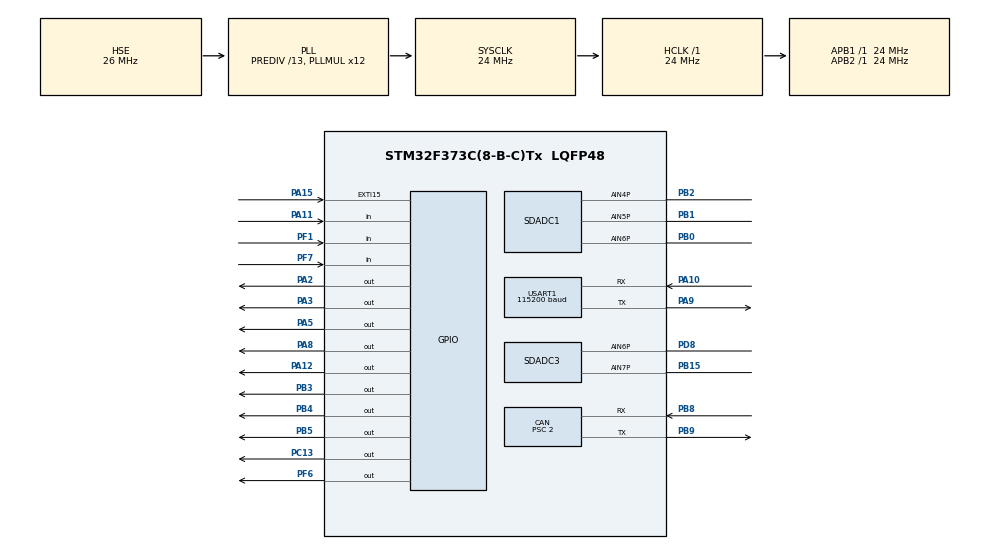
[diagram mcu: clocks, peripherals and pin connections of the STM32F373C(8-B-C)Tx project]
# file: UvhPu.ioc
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CAN.BS1=CAN_BS1_10TQ
CAN.BS2=CAN_BS2_1TQ
CAN.CalculateBaudRate=1000000
CAN.CalculateTimeBit=1000
CAN.CalculateTimeQuantum=83.33333333333333
CAN.Prescaler=2
Mcu.Family=STM32F3
Mcu.Name=STM32F373C(8-B-C)Tx
Mcu.Package=LQFP48
NVIC.CAN_RX0_IRQn=true\:0\:0\:false\:false\:true\:true\:true\:true
NVIC.EXTI15_10_IRQn=true\:0\:0\:false\:false\:true\:true\:true\:true
NVIC.PriorityGroup=NVIC_PRIORITYGROUP_4
NVIC.SDADC1_IRQn=true\:0\:0\:false\:false\:true\:true\:true\:true
NVIC.SDADC3_IRQn=true\:0\:0\:false\:false\:true\:true\:true\:true
NVIC.USART1_IRQn=true\:0\:0\:false\:false\:true\:true\:true\:true
PA10.Mode=Asynchronous
PA10.Signal=USART1_RX
PA11.GPIO_PuPd=GPIO_PULLUP
PA11.Signal=GPIO_Input
PA12.Signal=GPIO_Output
PA13.Mode=Serial_Wire
PA13.Signal=SYS_JTMS-SWDIO
PA14.Mode=Serial_Wire
PA14.Signal=SYS_JTCK-SWCLK
PA15.GPIO_ModeDefaultEXTI=GPIO_MODE_IT_FALLING
PA15.GPIO_PuPd=GPIO_PULLUP
PA15.Signal=GPXTI15
PA2.Signal=GPIO_Output
PA3.GPIO_PuPd=GPIO_PULLUP
PA3.Signal=GPIO_Output
PA5.Signal=GPIO_Output
PA8.Signal=GPIO_Output
PA9.Mode=Asynchronous
PA9.Signal=USART1_TX
PB0.Mode=IN6-Single-Ended
PB0.Signal=SDADC1_AIN6P
PB1.Mode=IN5-Single-Ended
PB1.Signal=SDADC1_AIN5P
PB15.Mode=IN7-Single-Ended
PB15.Signal=SDADC3_AIN7P
PB2.Mode=IN4-Single-Ended
PB2.Signal=SDADC1_AIN4P
PB3.Signal=GPIO_Output
PB4.Signal=GPIO_Output
PB5.Signal=GPIO_Output
PB8.Mode=CAN_Activate
PB8.Signal=CAN_RX
PB9.Mode=CAN_Activate
PB9.Signal=CAN_TX
PC13.Signal=GPIO_Output
PC14-OSC32_IN.Mode=LSE-External-Oscillator
PC14-OSC32_IN.Signal=RCC_OSC32_IN
PC15-OSC32_OUT.Mode=LSE-External-Oscillator
PC15-OSC32_OUT.Signal=RCC_OSC32_OUT
PD8.Mode=IN6-Single-Ended
PD8.Signal=SDADC3_AIN6P
PF0-OSC_IN.Mode=HSE-External-Clock-Source
PF0-OSC_IN.Signal=RCC_OSC_IN
PF1-OSC_OUT.GPIO_PuPd=GPIO_PULLDOWN
PF1-OSC_OUT.Signal=GPIO_Input
PF6.GPIO_ModeDefaultOutputPP=GPIO_MODE_OUTPUT_PP
PF6.GPIO_PuPd=GPIO_PULLUP
PF6.PinState=GPIO_PIN_SET
PF6.Signal=GPIO_Output
PF7.Signal=GPIO_Input
ProjectManager.HeapSize=0x200
ProjectManager.StackSize=0x400
ProjectManager.TargetToolchain=STM32CubeIDE
RCC.AHBFreq_Value=24000000
RCC.APB1Freq_Value=24000000
RCC.APB1TimFreq_Value=24000000
RCC.APB2Freq_Value=24000000
RCC.APB2TimFreq_Value=24000000
RCC.CortexFreq_Value=24000000
RCC.HCLKFreq_Value=24000000
RCC.HSE_VALUE=26000000
RCC.HSI_VALUE=8000000
RCC.PLLMUL=RCC_PLL_MUL12
RCC.PLLSourceVirtual=RCC_PLLSOURCE_HSE
RCC.RCC_PLLsource_Clock_Source_FROM_HSE=RCC_HSE_PREDIV_DIV13
RCC.SDADCPresc=RCC_SDADCSYSCLK_DIV4
RCC.SYSCLKFreq_VALUE=24000000
RCC.SYSCLKSource=RCC_SYSCLKSOURCE_PLLCLK
RCC.USBFreq_Value=24000000
RCC.Usart1ClockSelection=RCC_USART1CLKSOURCE_SYSCLK
SDADC1.Channel-0\#ChannelRegularConversion=SDADC_CHANNEL_6
SDADC1.ConfIndex-0\#ChannelRegularConversion=SDADC_CONF_INDEX_0
SDADC1.EnableInjectedConversion=ENABLE
SDADC1.EnableRegularconversion=DISABLE
SDADC1.Gain0=SDADC_GAIN_1_2
SDADC1.InjDelay=Enable
SDADC1.InjNumberOfConversion=3
SDADC1.InjectedChannel-1\#ChannelInjectedConversion=SDADC_CHANNEL_5
SDADC1.InjectedChannel-2\#ChannelInjectedConversion=SDADC_CHANNEL_6
SDADC1.InjectedChannel-3\#ChannelInjectedConversion=SDADC_CHANNEL_4
SDADC1.InjectedChannelsSelection=SDADC_CHANNEL_5|SDADC_CHANNEL_6|SDADC_CHANNEL_4
SDADC1.InjectedConfIndex-1\#ChannelInjectedConversion=SDADC_CONF_INDEX_0
SDADC1.InjectedConfIndex-2\#ChannelInjectedConversion=SDADC_CONF_INDEX_0
SDADC1.InjectedConfIndex-3\#ChannelInjectedConversion=SDADC_CONF_INDEX_0
SDADC1.InjectedContinuousMode=SDADC_CONTINUOUS_CONV_ON
SDADC1.InjectedRank-1\#ChannelInjectedConversion=1
SDADC1.InjectedRank-2\#ChannelInjectedConversion=2
SDADC1.InjectedRank-3\#ChannelInjectedConversion=3
SDADC1.InjectedTrigger=SDADC_SOFTWARE_TRIGGER
SDADC1.InputMode0=SDADC_INPUT_MODE_SE_OFFSET
SDADC1.NbrOfConversionFlag=1
SDADC1.Offset0=0
SDADC3.EnableInjectedConversion=ENABLE
SDADC3.EnableRegularconversion=DISABLE
SDADC3.Gain0=SDADC_GAIN_1_2
SDADC3.InjDelay=Enable
SDADC3.InjNumberOfConversion=2
SDADC3.InjectedChannel-0\#ChannelInjectedConversion=SDADC_CHANNEL_6
SDADC3.InjectedChannel-1\#ChannelInjectedConversion=SDADC_CHANNEL_7
SDADC3.InjectedChannelsSelection=SDADC_CHANNEL_6|SDADC_CHANNEL_7
SDADC3.InjectedConfIndex-0\#ChannelInjectedConversion=SDADC_CONF_INDEX_0
SDADC3.InjectedConfIndex-1\#ChannelInjectedConversion=SDADC_CONF_INDEX_0
SDADC3.InjectedContinuousMode=SDADC_CONTINUOUS_CONV_ON
SDADC3.InjectedRank-0\#ChannelInjectedConversion=1
SDADC3.InjectedRank-1\#ChannelInjectedConversion=2
SDADC3.InjectedTrigger=SDADC_SOFTWARE_TRIGGER
SDADC3.InputMode0=SDADC_INPUT_MODE_SE_OFFSET
SDADC3.NbrOfConversionFlag=1
SDADC3.Offset0=0
USART1.BaudRate=115200
USART1.VirtualMode-Asynchronous=VM_ASYNC
VP_SDADC1_CONF0.Mode=ConfigZero
VP_SDADC3_CONF0.Mode=ConfigZero
board=custom

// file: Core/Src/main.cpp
/* USER CODE BEGIN Header */
/**
  ******************************************************************************
  * @file           : main.c
  * @brief          : Main program body
  ******************************************************************************
  * @attention
  *
  * Copyright (c) 2023 STMicroelectronics.
  * All rights reserved.
  *
  * This software is licensed under terms that can be found in the LICENSE file
  * in the root directory of this software component.
  * If no LICENSE file comes with this software, it is provided AS-IS.
  *
  ******************************************************************************
  */
/* USER CODE END Header */
#include "main.h"

/* USER CODE BEGIN Includes */
#include "app.h"
/* USER CODE END Includes */

CAN_HandleTypeDef hcan;

SDADC_HandleTypeDef hsdadc1;
SDADC_HandleTypeDef hsdadc3;

UART_HandleTypeDef huart1;

void SystemClock_Config(void);
static void MX_GPIO_Init(void);
static void MX_CAN_Init(void);
static void MX_SDADC1_Init(void);
static void MX_SDADC3_Init(void);
static void MX_USART1_UART_Init(void);

int main(void)
{

  /* MCU Configuration--------------------------------------------------------*/

  /* Reset of all peripherals, Initializes the Flash interface and the Systick. */
  HAL_Init();

  /* Configure the system clock */
  SystemClock_Config();

  /* Initialize all configured peripherals */
  MX_GPIO_Init();
  MX_CAN_Init();
  MX_SDADC1_Init();
  MX_SDADC3_Init();
  MX_USART1_UART_Init();
  /* USER CODE BEGIN 2 */

  HAL_SDADC_InjectedStart_IT(&hsdadc1);
  HAL_SDADC_InjectedStart_IT(&hsdadc3);

  initialization();

  /* USER CODE END 2 */

  /* Infinite loop */
  /* USER CODE BEGIN WHILE */
  while (1)
  {
      exec();

    /* USER CODE END WHILE */

  }
}

void SystemClock_Config(void)
{
  RCC_OscInitTypeDef RCC_OscInitStruct = {0};
  RCC_ClkInitTypeDef RCC_ClkInitStruct = {0};
  RCC_PeriphCLKInitTypeDef PeriphClkInit = {0};

  /** Initializes the RCC Oscillators according to the specified parameters
  * in the RCC_OscInitTypeDef structure.
  */
  RCC_OscInitStruct.OscillatorType = RCC_OSCILLATORTYPE_HSE;
  RCC_OscInitStruct.HSEState = RCC_HSE_BYPASS;
  RCC_OscInitStruct.HSEPredivValue = RCC_HSE_PREDIV_DIV13;
  RCC_OscInitStruct.HSIState = RCC_HSI_ON;
  RCC_OscInitStruct.PLL.PLLState = RCC_PLL_ON;
  RCC_OscInitStruct.PLL.PLLSource = RCC_PLLSOURCE_HSE;
  RCC_OscInitStruct.PLL.PLLMUL = RCC_PLL_MUL12;
  if (HAL_RCC_OscConfig(&RCC_OscInitStruct) != HAL_OK)
  {
    Error_Handler();
  }
  /** Initializes the CPU, AHB and APB buses clocks
  */
  RCC_ClkInitStruct.ClockType = RCC_CLOCKTYPE_HCLK|RCC_CLOCKTYPE_SYSCLK
                              |RCC_CLOCKTYPE_PCLK1|RCC_CLOCKTYPE_PCLK2;
  RCC_ClkInitStruct.SYSCLKSource = RCC_SYSCLKSOURCE_PLLCLK;
  RCC_ClkInitStruct.AHBCLKDivider = RCC_SYSCLK_DIV1;
  RCC_ClkInitStruct.APB1CLKDivider = RCC_HCLK_DIV1;
  RCC_ClkInitStruct.APB2CLKDivider = RCC_HCLK_DIV1;

  if (HAL_RCC_ClockConfig(&RCC_ClkInitStruct, FLASH_LATENCY_0) != HAL_OK)
  {
    Error_Handler();
  }
  PeriphClkInit.PeriphClockSelection = RCC_PERIPHCLK_USART1|RCC_PERIPHCLK_SDADC;
  PeriphClkInit.Usart1ClockSelection = RCC_USART1CLKSOURCE_SYSCLK;
  PeriphClkInit.SdadcClockSelection = RCC_SDADCSYSCLK_DIV4;
  if (HAL_RCCEx_PeriphCLKConfig(&PeriphClkInit) != HAL_OK)
  {
    Error_Handler();
  }
  HAL_PWREx_EnableSDADC(PWR_SDADC_ANALOG1);
  HAL_PWREx_EnableSDADC(PWR_SDADC_ANALOG3);
}

static void MX_CAN_Init(void)
{

  hcan.Instance = CAN;
  hcan.Init.Prescaler = 2;
  hcan.Init.Mode = CAN_MODE_NORMAL;
  hcan.Init.SyncJumpWidth = CAN_SJW_1TQ;
  hcan.Init.TimeSeg1 = CAN_BS1_10TQ;
  hcan.Init.TimeSeg2 = CAN_BS2_1TQ;
  hcan.Init.TimeTriggeredMode = DISABLE;
  hcan.Init.AutoBusOff = DISABLE;
  hcan.Init.AutoWakeUp = DISABLE;
  hcan.Init.AutoRetransmission = DISABLE;
  hcan.Init.ReceiveFifoLocked = DISABLE;
  hcan.Init.TransmitFifoPriority = DISABLE;
  if (HAL_CAN_Init(&hcan) != HAL_OK)
  {
    Error_Handler();
  }

}

static void MX_SDADC1_Init(void)
{

  SDADC_ConfParamTypeDef ConfParamStruct = {0};

  /** Configure the SDADC low power mode, fast conversion mode,
  slow clock mode and SDADC1 reference voltage
  */
  hsdadc1.Instance = SDADC1;
  hsdadc1.Init.IdleLowPowerMode = SDADC_LOWPOWER_NONE;
  hsdadc1.Init.FastConversionMode = SDADC_FAST_CONV_DISABLE;
  hsdadc1.Init.SlowClockMode = SDADC_SLOW_CLOCK_DISABLE;
  hsdadc1.Init.ReferenceVoltage = SDADC_VREF_EXT;
  hsdadc1.InjectedTrigger = SDADC_SOFTWARE_TRIGGER;
  if (HAL_SDADC_Init(&hsdadc1) != HAL_OK)
  {
    Error_Handler();
  }
  /** Configure the Injected Mode
  */
  if (HAL_SDADC_SelectInjectedDelay(&hsdadc1, SDADC_INJECTED_DELAY) != HAL_OK)
  {
    Error_Handler();
  }
  if (HAL_SDADC_SelectInjectedTrigger(&hsdadc1, SDADC_SOFTWARE_TRIGGER) != HAL_OK)
  {
    Error_Handler();
  }
  if (HAL_SDADC_InjectedConfigChannel(&hsdadc1, SDADC_CHANNEL_5|SDADC_CHANNEL_6
                              |SDADC_CHANNEL_4, SDADC_CONTINUOUS_CONV_ON) != HAL_OK)
  {
    Error_Handler();
  }
  /** Set parameters for SDADC configuration 0 Register
  */
  ConfParamStruct.InputMode = SDADC_INPUT_MODE_SE_OFFSET;
  ConfParamStruct.Gain = SDADC_GAIN_1_2;
  ConfParamStruct.CommonMode = SDADC_COMMON_MODE_VSSA;
  ConfParamStruct.Offset = 0;
  if (HAL_SDADC_PrepareChannelConfig(&hsdadc1, SDADC_CONF_INDEX_0, &ConfParamStruct) != HAL_OK)
  {
    Error_Handler();
  }
  /** Configure the Regular Channel
  */
  if (HAL_SDADC_AssociateChannelConfig(&hsdadc1, SDADC_CHANNEL_6, SDADC_CONF_INDEX_0) != HAL_OK)
  {
    Error_Handler();
  }
  /** Configure the Injected Channel
  */
  if (HAL_SDADC_AssociateChannelConfig(&hsdadc1, SDADC_CHANNEL_5, SDADC_CONF_INDEX_0) != HAL_OK)
  {
    Error_Handler();
  }
  /** Configure the Injected Channel
  */
  if (HAL_SDADC_AssociateChannelConfig(&hsdadc1, SDADC_CHANNEL_4, SDADC_CONF_INDEX_0) != HAL_OK)
  {
    Error_Handler();
  }

}

static void MX_SDADC3_Init(void)
{

  SDADC_ConfParamTypeDef ConfParamStruct = {0};

  /** Configure the SDADC low power mode, fast conversion mode,
  slow clock mode and SDADC1 reference voltage
  */
  hsdadc3.Instance = SDADC3;
  hsdadc3.Init.IdleLowPowerMode = SDADC_LOWPOWER_NONE;
  hsdadc3.Init.FastConversionMode = SDADC_FAST_CONV_DISABLE;
  hsdadc3.Init.SlowClockMode = SDADC_SLOW_CLOCK_DISABLE;
  hsdadc3.Init.ReferenceVoltage = SDADC_VREF_EXT;
  hsdadc3.InjectedTrigger = SDADC_SOFTWARE_TRIGGER;
  if (HAL_SDADC_Init(&hsdadc3) != HAL_OK)
  {
    Error_Handler();
  }
  /** Configure the Injected Mode
  */
  if (HAL_SDADC_SelectInjectedDelay(&hsdadc3, SDADC_INJECTED_DELAY) != HAL_OK)
  {
    Error_Handler();
  }
  if (HAL_SDADC_SelectInjectedTrigger(&hsdadc3, SDADC_SOFTWARE_TRIGGER) != HAL_OK)
  {
    Error_Handler();
  }
  if (HAL_SDADC_InjectedConfigChannel(&hsdadc3, SDADC_CHANNEL_6|SDADC_CHANNEL_7, SDADC_CONTINUOUS_CONV_ON) != HAL_OK)
  {
    Error_Handler();
  }
  /** Set parameters for SDADC configuration 0 Register
  */
  ConfParamStruct.InputMode = SDADC_INPUT_MODE_SE_OFFSET;
  ConfParamStruct.Gain = SDADC_GAIN_1_2;
  ConfParamStruct.CommonMode = SDADC_COMMON_MODE_VSSA;
  ConfParamStruct.Offset = 0;
  if (HAL_SDADC_PrepareChannelConfig(&hsdadc3, SDADC_CONF_INDEX_0, &ConfParamStruct) != HAL_OK)
  {
    Error_Handler();
  }
  /** Configure the Injected Channel
  */
  if (HAL_SDADC_AssociateChannelConfig(&hsdadc3, SDADC_CHANNEL_6, SDADC_CONF_INDEX_0) != HAL_OK)
  {
    Error_Handler();
  }
  /** Configure the Injected Channel
  */
  if (HAL_SDADC_AssociateChannelConfig(&hsdadc3, SDADC_CHANNEL_7, SDADC_CONF_INDEX_0) != HAL_OK)
  {
    Error_Handler();
  }
  /* USER CODE BEGIN SDADC3_Init 2 */
  HAL_SDADC_CalibrationStart(&hsdadc3, SDADC_CALIBRATION_SEQ_1);
  HAL_SDADC_PollForCalibEvent(&hsdadc3, HAL_MAX_DELAY);
  /* USER CODE END SDADC3_Init 2 */

}

static void MX_USART1_UART_Init(void)
{

  huart1.Instance = USART1;
  huart1.Init.BaudRate = 115200;
  huart1.Init.WordLength = UART_WORDLENGTH_8B;
  huart1.Init.StopBits = UART_STOPBITS_1;
  huart1.Init.Parity = UART_PARITY_NONE;
  huart1.Init.Mode = UART_MODE_TX_RX;
  huart1.Init.HwFlowCtl = UART_HWCONTROL_NONE;
  huart1.Init.OverSampling = UART_OVERSAMPLING_16;
  huart1.Init.OneBitSampling = UART_ONE_BIT_SAMPLE_DISABLE;
  huart1.AdvancedInit.AdvFeatureInit = UART_ADVFEATURE_NO_INIT;
  if (HAL_UART_Init(&huart1) != HAL_OK)
  {
    Error_Handler();
  }

}

static void MX_GPIO_Init(void)
{
  GPIO_InitTypeDef GPIO_InitStruct = {0};

  /* GPIO Ports Clock Enable */
  __HAL_RCC_GPIOC_CLK_ENABLE();
  __HAL_RCC_GPIOF_CLK_ENABLE();
  __HAL_RCC_GPIOA_CLK_ENABLE();
  __HAL_RCC_GPIOB_CLK_ENABLE();
  __HAL_RCC_GPIOD_CLK_ENABLE();

  /*Configure GPIO pin Output Level */
  HAL_GPIO_WritePin(GPIOC, GPIO_PIN_13, GPIO_PIN_RESET);

  /*Configure GPIO pin Output Level */
  HAL_GPIO_WritePin(GPIOA, GPIO_PIN_2|GPIO_PIN_3|GPIO_PIN_5|GPIO_PIN_8
                          |GPIO_PIN_12, GPIO_PIN_RESET);

  /*Configure GPIO pin Output Level */
  HAL_GPIO_WritePin(GPIOF, GPIO_PIN_6, GPIO_PIN_SET);

  /*Configure GPIO pin Output Level */
  HAL_GPIO_WritePin(GPIOB, GPIO_PIN_3|GPIO_PIN_4|GPIO_PIN_5, GPIO_PIN_RESET);

  /*Configure GPIO pin : PC13 */
  GPIO_InitStruct.Pin = GPIO_PIN_13;
  GPIO_InitStruct.Mode = GPIO_MODE_OUTPUT_PP;
  GPIO_InitStruct.Pull = GPIO_NOPULL;
  GPIO_InitStruct.Speed = GPIO_SPEED_FREQ_LOW;
  HAL_GPIO_Init(GPIOC, &GPIO_InitStruct);

  /*Configure GPIO pin : PF1 */
  GPIO_InitStruct.Pin = GPIO_PIN_1;
  GPIO_InitStruct.Mode = GPIO_MODE_INPUT;
  GPIO_InitStruct.Pull = GPIO_PULLDOWN;
  HAL_GPIO_Init(GPIOF, &GPIO_InitStruct);

  /*Configure GPIO pins : PA2 PA5 PA8 PA12 */
  GPIO_InitStruct.Pin = GPIO_PIN_2|GPIO_PIN_5|GPIO_PIN_8|GPIO_PIN_12;
  GPIO_InitStruct.Mode = GPIO_MODE_OUTPUT_PP;
  GPIO_InitStruct.Pull = GPIO_NOPULL;
  GPIO_InitStruct.Speed = GPIO_SPEED_FREQ_LOW;
  HAL_GPIO_Init(GPIOA, &GPIO_InitStruct);

  /*Configure GPIO pin : PA3 */
  GPIO_InitStruct.Pin = GPIO_PIN_3;
  GPIO_InitStruct.Mode = GPIO_MODE_OUTPUT_PP;
  GPIO_InitStruct.Pull = GPIO_PULLUP;
  GPIO_InitStruct.Speed = GPIO_SPEED_FREQ_LOW;
  HAL_GPIO_Init(GPIOA, &GPIO_InitStruct);

  /*Configure GPIO pin : PA11 */
  GPIO_InitStruct.Pin = GPIO_PIN_11;
  GPIO_InitStruct.Mode = GPIO_MODE_INPUT;
  GPIO_InitStruct.Pull = GPIO_PULLUP;
  HAL_GPIO_Init(GPIOA, &GPIO_InitStruct);

  /*Configure GPIO pin : PF6 */
  GPIO_InitStruct.Pin = GPIO_PIN_6;
  GPIO_InitStruct.Mode = GPIO_MODE_OUTPUT_PP;
  GPIO_InitStruct.Pull = GPIO_PULLUP;
  GPIO_InitStruct.Speed = GPIO_SPEED_FREQ_LOW;
  HAL_GPIO_Init(GPIOF, &GPIO_InitStruct);

  /*Configure GPIO pin : PF7 */
  GPIO_InitStruct.Pin = GPIO_PIN_7;
  GPIO_InitStruct.Mode = GPIO_MODE_INPUT;
  GPIO_InitStruct.Pull = GPIO_NOPULL;
  HAL_GPIO_Init(GPIOF, &GPIO_InitStruct);

  /*Configure GPIO pin : PA15 */
  GPIO_InitStruct.Pin = GPIO_PIN_15;
  GPIO_InitStruct.Mode = GPIO_MODE_IT_FALLING;
  GPIO_InitStruct.Pull = GPIO_PULLUP;
  HAL_GPIO_Init(GPIOA, &GPIO_InitStruct);

  /*Configure GPIO pins : PB3 PB4 PB5 */
  GPIO_InitStruct.Pin = GPIO_PIN_3|GPIO_PIN_4|GPIO_PIN_5;
  GPIO_InitStruct.Mode = GPIO_MODE_OUTPUT_PP;
  GPIO_InitStruct.Pull = GPIO_NOPULL;
  GPIO_InitStruct.Speed = GPIO_SPEED_FREQ_LOW;
  HAL_GPIO_Init(GPIOB, &GPIO_InitStruct);

  /* EXTI interrupt init*/
  HAL_NVIC_SetPriority(EXTI15_10_IRQn, 0, 0);
  HAL_NVIC_EnableIRQ(EXTI15_10_IRQn);

}

void Error_Handler(void)
{
  __disable_irq();
  while (1)
  {
  }
}
